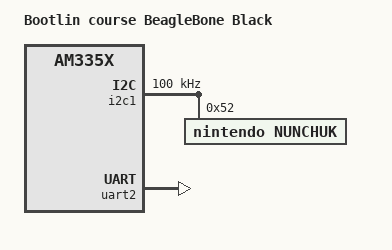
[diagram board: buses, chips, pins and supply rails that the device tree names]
// SPDX-License-Identifier: GPL-2.0-only
#include "am335x-boneblack.dts"

/ {
	model = "Bootlin course BeagleBone Black";
};

&am33xx_pinmux {
    i2c1_pins: pinmux_i2c1_pins {
		pinctrl-single,pins = <
			AM33XX_PADCONF(AM335X_PIN_SPI0_D1, PIN_INPUT_PULLUP, MUX_MODE2)	/* spi0_d1.i2c1_sda */
			AM33XX_PADCONF(AM335X_PIN_SPI0_CS0, PIN_INPUT_PULLUP, MUX_MODE2)	/* spi0_cs0.i2c1_scl */
		>;
	};
    uart2_pins: uart2_pins {
        pinctrl-single,pins = <
            AM33XX_PADCONF(AM335X_PIN_SPI0_SCLK, PIN_INPUT_PULLUP, MUX_MODE1) /* (A17) spi0_sclk.uart2_rxd */
            AM33XX_PADCONF(AM335X_PIN_SPI0_D0, PIN_OUTPUT, MUX_MODE1) /* (B17) spi0_d0.uart2_txd */
        >;
    };
    uart4_pins: uart4_pins {
        pinctrl-single,pins = <
            AM33XX_PADCONF(AM335X_PIN_GPMC_WAIT0, PIN_INPUT_PULLUP, MUX_MODE6) /* (T17) gpmc_wait0.uart4_rxd */
            AM33XX_PADCONF(AM335X_PIN_GPMC_WPN, PIN_OUTPUT, MUX_MODE6) /* (U17) gpmc_wpn.uart4_txd */
        >;
    };
};

&i2c1 {
    pinctrl-names = "default";
    pinctrl-0 = <&i2c1_pins>;

    status = "okay";
    clock-frequency = <0x186a0>;

    nunchuk: joystick@52 {
        compatible = "nintendo,nunchuk";
        reg = <0x52>;
    };
};

&uart2 {
    compatible = "bootlin,serial";
    status = "okay";
    pinctrl-names = "default";
    pinctrl-0 = <&uart2_pins>;
};

&uart2 {
    compatible = "bootlin,serial";
    status = "okay";
    pinctrl-names = "default";
    pinctrl-0 = <&uart4_pins>;
};

// &i2c2 {
//     nunchuk2: joystick@52 {
//         compatible = "nintendo,nunchuk";
//         reg = <0x52>;
//     };
// };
